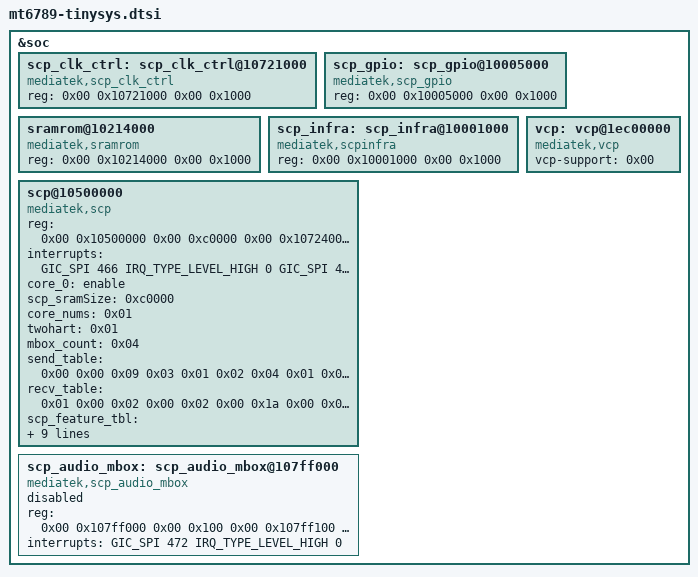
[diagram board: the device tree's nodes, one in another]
// SPDX-License-Identifier: (GPL-2.0 OR MIT)
/* MT6789 tinysys blocks - split out of the soc node by tools/scripts/dts-socsplit.py */

&soc {
	scp_clk_ctrl: scp_clk_ctrl@10721000 {
		compatible = "mediatek,scp_clk_ctrl", "syscon";
		reg = <0x00 0x10721000 0x00 0x1000>;
	};

	scp_gpio: scp_gpio@10005000 {
		compatible = "mediatek,scp_gpio", "syscon";
		reg = <0x00 0x10005000 0x00 0x1000>;
	};

	sramrom@10214000 {
		compatible = "mediatek,sramrom";
		reg = <0x00 0x10214000 0x00 0x1000>;
	};

	scp_infra: scp_infra@10001000 {
		compatible = "mediatek,scpinfra";
		reg = <0x00 0x10001000 0x00 0x1000>;
		#clock-cells = <0x01>;
	};

	scp@10500000 {
		compatible = "mediatek,scp";
		status = "okay";
		reg = <0x00 0x10500000 0x00 0xc0000 0x00 0x10724000 0x00 0x1000 0x00 0x10721000 0x00 0x1000 0x00 0x10730000 0x00 0x3000 0x00 0x10740000 0x00 0x1000 0x00 0x10752000 0x00 0x1000 0x00 0x10760000 0x00 0x40000 0x00 0x107a5000 0x00 0x04 0x00 0x107fb000 0x00 0x100 0x00 0x107fb100 0x00 0x04 0x00 0x107fb10c 0x00 0x04 0x00 0x107a5020 0x00 0x04 0x00 0x107fc000 0x00 0x100 0x00 0x107fc100 0x00 0x04 0x00 0x107fc10c 0x00 0x04 0x00 0x107a5024 0x00 0x04 0x00 0x107fd000 0x00 0x100 0x00 0x107fd100 0x00 0x04 0x00 0x107fd10c 0x00 0x04 0x00 0x107a5028 0x00 0x04 0x00 0x107fe000 0x00 0x100 0x00 0x107fe100 0x00 0x04 0x00 0x107fe10c 0x00 0x04 0x00 0x107a502c 0x00 0x04 0x00 0x107ff000 0x00 0x100 0x00 0x107ff100 0x00 0x04 0x00 0x107ff10c 0x00 0x04 0x00 0x107a5030 0x00 0x04>;
		reg-names = "scp_sram_base", "scp_cfgreg", "scp_clkreg", "scp_cfgreg_core0", "scp_cfgreg_core1", "scp_bus_tracker", "scp_l1creg", "scp_cfgreg_sec", "mbox0_base", "mbox0_set", "mbox0_clr", "mbox0_init", "mbox1_base", "mbox1_set", "mbox1_clr", "mbox1_init", "mbox2_base", "mbox2_set", "mbox2_clr", "mbox2_init", "mbox3_base", "mbox3_set", "mbox3_clr", "mbox3_init", "mbox4_base", "mbox4_set", "mbox4_clr", "mbox4_init";
		interrupts = <GIC_SPI 466 IRQ_TYPE_LEVEL_HIGH 0 GIC_SPI 467 IRQ_TYPE_LEVEL_HIGH 0 GIC_SPI 468 IRQ_TYPE_LEVEL_HIGH 0 GIC_SPI 469 IRQ_TYPE_LEVEL_HIGH 0 GIC_SPI 470 IRQ_TYPE_LEVEL_HIGH 0 GIC_SPI 471 IRQ_TYPE_LEVEL_HIGH 0 GIC_SPI 472 IRQ_TYPE_LEVEL_HIGH 0>;
		interrupt-names = "ipc0", "ipc1", "mbox0", "mbox1", "mbox2", "mbox3", "mbox4";
		core_0 = "enable";
		scp_sramSize = <0xc0000>;
		core_nums = <0x01>;
		twohart = <0x01>;
		mbox_count = <0x04>;
		send_table = <0x00 0x00 0x09 0x03 0x01 0x02 0x04 0x01 0x01 0x05 0x01 0x02 0x06 0x01 0x01 0x1a 0x01 0x09 0x1d 0x02 0x10 0x1f 0x02 0x07 0x29 0x02 0x02 0x2b 0x02 0x0a 0x0e 0x03 0x01 0x0f 0x03 0x02 0x10 0x03 0x01 0x11 0x03 0x06 0x12 0x03 0x02>;
		recv_table = <0x01 0x00 0x02 0x00 0x02 0x00 0x1a 0x00 0x07 0x01 0x02 0x00 0x08 0x01 0x0a 0x00 0x09 0x01 0x01 0x00 0x0a 0x01 0x02 0x00 0x1b 0x01 0x02 0x00 0x1c 0x01 0x05 0x00 0x05 0x01 0x01 0x01 0x1e 0x02 0x02 0x00 0x20 0x02 0x07 0x00 0x2c 0x02 0x0a 0x00 0x14 0x03 0x0a 0x00 0x15 0x03 0x06 0x00 0x16 0x03 0x01 0x00 0x17 0x03 0x02 0x00 0x0f 0x03 0x01 0x01>;
		scp_feature_tbl = <0x00 0x05 0x01 0x01 0x00 0x00 0x02 0x1a 0x00 0x03 0x00 0x00 0x04 0xc8 0x01 0x05 0x00 0x00 0x06 0x78 0x01 0x07 0x0a 0x01 0x08 0x50 0x01 0x09 0x2b 0x01 0x0a 0x16 0x01 0x0b 0x14 0x01 0x0c 0x87 0x01 0x0d 0x2bc 0x00>;
		debug_dumptimeout = "enable";
		secure_dump = "enable";
		secure_dump_size = <0x200000>;
		scp_mem_key = "mediatek,reserve-memory-scp_share";
		scp_mem_tbl = <0x00 0x00 0x00 0x01 0x4e300 0x00 0x02 0x100000 0x00 0x03 0x180000 0x00 0x04 0x200000 0x00 0x05 0x5a00 0x00 0x06 0x100 0x00 0x07 0x19000 0x00 0x08 0x10000 0x00 0x09 0x1000 0x00 0x0a 0x2000 0x00 0x0b 0x100 0x00 0x0c 0x100 0x00 0x0e 0x8000 0x00>;
		memorydump = <0xc0000 0x3c000 0x3c00 0x400 0x100000>;
	};

	scp_audio_mbox: scp_audio_mbox@107ff000 {
		compatible = "mediatek,scp_audio_mbox";
		status = "disabled";
		reg = <0x00 0x107ff000 0x00 0x100 0x00 0x107ff100 0x00 0x04 0x00 0x107ff10c 0x00 0x04>;
		reg-names = "mbox0_base", "mbox0_set", "mbox0_clr";
		interrupts = <GIC_SPI 472 IRQ_TYPE_LEVEL_HIGH 0>;
		interrupt-names = "mbox0";
	};

	vcp: vcp@1ec00000 {
		compatible = "mediatek,vcp";
		vcp-support = <0x00>;
		status = "okay";
	};

};
